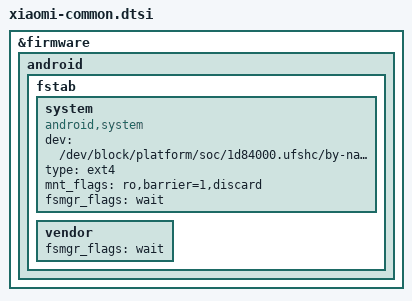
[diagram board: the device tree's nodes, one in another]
/* Copyright (c) 2016-2019, The Linux Foundation. All rights reserved.
 * Copyright (C) 2019 XiaoMi, Inc.
 *
 * This program is free software; you can redistribute it and/or modify
 * it under the terms of the GNU General Public License version 2 and
 * only version 2 as published by the Free Software Foundation.
 *
 * This program is distributed in the hope that it will be useful,
 * but WITHOUT ANY WARRANTY; without even the implied warranty of
 * MERCHANTABILITY or FITNESS FOR A PARTICULAR PURPOSE.  See the
 * GNU General Public License for more details.
 */

#include "xiaomi-sde-display.dtsi"

&firmware {
	android {
		/delete-node/ vbmeta;

		fstab {
			system {
				compatible = "android,system";
				dev = "/dev/block/platform/soc/1d84000.ufshc/by-name/system";
				type = "ext4";
				mnt_flags = "ro,barrier=1,discard";
				fsmgr_flags = "wait";
				status = "ok";
			};
			vendor {
				fsmgr_flags = "wait";
			};
		};
	};
};
